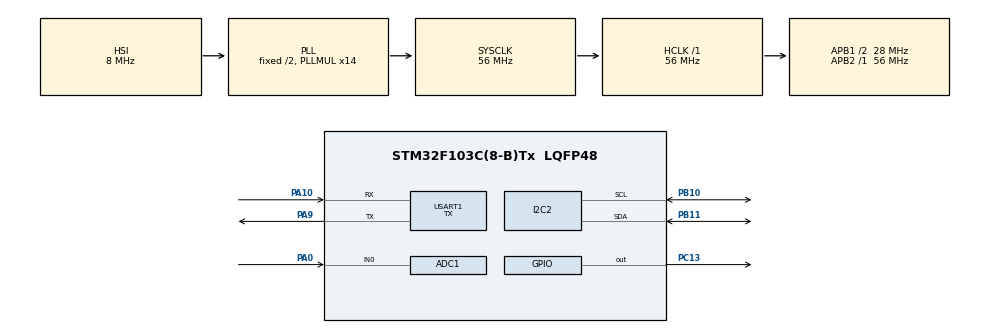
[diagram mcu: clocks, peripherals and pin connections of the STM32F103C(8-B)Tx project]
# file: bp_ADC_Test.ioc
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ADC1.Channel-0\#ChannelRegularConversion=ADC_CHANNEL_0
ADC1.NbrOfConversionFlag=1
ADC1.Rank-0\#ChannelRegularConversion=1
ADC1.SamplingTime-0\#ChannelRegularConversion=ADC_SAMPLETIME_1CYCLE_5
ADC1.master=1
I2C2.I2C_Mode=I2C_Fast
Mcu.Family=STM32F1
Mcu.Name=STM32F103C(8-B)Tx
Mcu.Package=LQFP48
NVIC.PriorityGroup=NVIC_PRIORITYGROUP_4
PA0-WKUP.Signal=ADCx_IN0
PA10.Mode=Asynchronous
PA10.Signal=USART1_RX
PA13.Mode=Serial_Wire
PA13.Signal=SYS_JTMS-SWDIO
PA14.Mode=Serial_Wire
PA14.Signal=SYS_JTCK-SWCLK
PA9.Mode=Asynchronous
PA9.Signal=USART1_TX
PB10.Mode=I2C
PB10.Signal=I2C2_SCL
PB11.Mode=I2C
PB11.Signal=I2C2_SDA
PC13-TAMPER-RTC.Signal=GPIO_Output
ProjectManager.HeapSize=0x200
ProjectManager.StackSize=0x400
ProjectManager.TargetToolchain=TrueSTUDIO
RCC.ADCPresc=RCC_ADCPCLK2_DIV4
RCC.AHBFreq_Value=56000000
RCC.APB1CLKDivider=RCC_HCLK_DIV2
RCC.APB1Freq_Value=28000000
RCC.APB1TimFreq_Value=56000000
RCC.APB2Freq_Value=56000000
RCC.APB2TimFreq_Value=56000000
RCC.HCLKFreq_Value=56000000
RCC.PLLMUL=RCC_PLL_MUL14
RCC.SYSCLKFreq_VALUE=56000000
RCC.SYSCLKSource=RCC_SYSCLKSOURCE_PLLCLK
RCC.USBFreq_Value=56000000
SH.ADCx_IN0.0=ADC1_IN0,IN0
USART1.Mode=MODE_TX
USART1.VirtualMode=VM_ASYNC
board=custom

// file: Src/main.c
/* USER CODE BEGIN Header */
/**
  ******************************************************************************
  * @file           : main.c
  * @brief          : Main program body
  ******************************************************************************
  ** This notice applies to any and all portions of this file
  * that are not between comment pairs USER CODE BEGIN and
  * USER CODE END. Other portions of this file, whether
  * inserted by the user or by software development tools
  * are owned by their respective copyright owners.
  *
  * COPYRIGHT(c) 2019 STMicroelectronics
  *
  * Redistribution and use in source and binary forms, with or without modification,
  * are permitted provided that the following conditions are met:
  *   1. Redistributions of source code must retain the above copyright notice,
  *      this list of conditions and the following disclaimer.
  *   2. Redistributions in binary form must reproduce the above copyright notice,
  *      this list of conditions and the following disclaimer in the documentation
  *      and/or other materials provided with the distribution.
  *   3. Neither the name of STMicroelectronics nor the names of its contributors
  *      may be used to endorse or promote products derived from this software
  *      without specific prior written permission.
  *
  * THIS SOFTWARE IS PROVIDED BY THE COPYRIGHT HOLDERS AND CONTRIBUTORS "AS IS"
  * AND ANY EXPRESS OR IMPLIED WARRANTIES, INCLUDING, BUT NOT LIMITED TO, THE
  * IMPLIED WARRANTIES OF MERCHANTABILITY AND FITNESS FOR A PARTICULAR PURPOSE ARE
  * DISCLAIMED. IN NO EVENT SHALL THE COPYRIGHT HOLDER OR CONTRIBUTORS BE LIABLE
  * FOR ANY DIRECT, INDIRECT, INCIDENTAL, SPECIAL, EXEMPLARY, OR CONSEQUENTIAL
  * DAMAGES (INCLUDING, BUT NOT LIMITED TO, PROCUREMENT OF SUBSTITUTE GOODS OR
  * SERVICES; LOSS OF USE, DATA, OR PROFITS; OR BUSINESS INTERRUPTION) HOWEVER
  * CAUSED AND ON ANY THEORY OF LIABILITY, WHETHER IN CONTRACT, STRICT LIABILITY,
  * OR TORT (INCLUDING NEGLIGENCE OR OTHERWISE) ARISING IN ANY WAY OUT OF THE USE
  * OF THIS SOFTWARE, EVEN IF ADVISED OF THE POSSIBILITY OF SUCH DAMAGE.
  *
  ******************************************************************************
  */
/* USER CODE END Header */

#include "main.h"

/* USER CODE BEGIN Includes */
#include "print_UART.h"

/* USER CODE END Includes */

ADC_HandleTypeDef hadc1;

I2C_HandleTypeDef hi2c2;

UART_HandleTypeDef huart1;

void SystemClock_Config(void);
static void MX_GPIO_Init(void);
static void MX_USART1_UART_Init(void);
static void MX_ADC1_Init(void);
static void MX_I2C2_Init(void);

int main(void)
{

  /* MCU Configuration--------------------------------------------------------*/

  /* Reset of all peripherals, Initializes the Flash interface and the Systick. */
  HAL_Init();

  /* Configure the system clock */
  SystemClock_Config();

  /* Initialize all configured peripherals */
  MX_GPIO_Init();
  MX_USART1_UART_Init();
  MX_ADC1_Init();
  MX_I2C2_Init();
  /* USER CODE BEGIN 2 */
  HAL_ADCEx_Calibration_Start(&hadc1);

  static uint16_t data_adc;
  static float data_adc_float;
  static float media=0;

  /* USER CODE END 2 */

  /* Infinite loop */
  /* USER CODE BEGIN WHILE */
  while (1)
  {

	  for (uint8_t i=0; i<50; i++){
		  HAL_ADC_Start(&hadc1);
		  HAL_ADC_PollForConversion(&hadc1, 1000);
		  data_adc = HAL_ADC_GetValue(&hadc1);
		  HAL_ADC_Stop(&hadc1);
		  data_adc_float = data_adc;
		  media = (media*i + data_adc_float*3.3/4095) / (i+1);

		  HAL_Delay(50);
	  }

	  tx_UART_float(&huart1, media,2, 10);
    /* USER CODE END WHILE */

  }
}

void SystemClock_Config(void)
{
  RCC_OscInitTypeDef RCC_OscInitStruct = {0};
  RCC_ClkInitTypeDef RCC_ClkInitStruct = {0};
  RCC_PeriphCLKInitTypeDef PeriphClkInit = {0};

  /**Initializes the CPU, AHB and APB busses clocks
  */
  RCC_OscInitStruct.OscillatorType = RCC_OSCILLATORTYPE_HSI;
  RCC_OscInitStruct.HSIState = RCC_HSI_ON;
  RCC_OscInitStruct.HSICalibrationValue = RCC_HSICALIBRATION_DEFAULT;
  RCC_OscInitStruct.PLL.PLLState = RCC_PLL_ON;
  RCC_OscInitStruct.PLL.PLLSource = RCC_PLLSOURCE_HSI_DIV2;
  RCC_OscInitStruct.PLL.PLLMUL = RCC_PLL_MUL14;
  if (HAL_RCC_OscConfig(&RCC_OscInitStruct) != HAL_OK)
  {
    Error_Handler();
  }
  /**Initializes the CPU, AHB and APB busses clocks
  */
  RCC_ClkInitStruct.ClockType = RCC_CLOCKTYPE_HCLK|RCC_CLOCKTYPE_SYSCLK
                              |RCC_CLOCKTYPE_PCLK1|RCC_CLOCKTYPE_PCLK2;
  RCC_ClkInitStruct.SYSCLKSource = RCC_SYSCLKSOURCE_PLLCLK;
  RCC_ClkInitStruct.AHBCLKDivider = RCC_SYSCLK_DIV1;
  RCC_ClkInitStruct.APB1CLKDivider = RCC_HCLK_DIV2;
  RCC_ClkInitStruct.APB2CLKDivider = RCC_HCLK_DIV1;

  if (HAL_RCC_ClockConfig(&RCC_ClkInitStruct, FLASH_LATENCY_2) != HAL_OK)
  {
    Error_Handler();
  }
  PeriphClkInit.PeriphClockSelection = RCC_PERIPHCLK_ADC;
  PeriphClkInit.AdcClockSelection = RCC_ADCPCLK2_DIV4;
  if (HAL_RCCEx_PeriphCLKConfig(&PeriphClkInit) != HAL_OK)
  {
    Error_Handler();
  }
}

static void MX_ADC1_Init(void)
{

  ADC_ChannelConfTypeDef sConfig = {0};

  /**Common config
  */
  hadc1.Instance = ADC1;
  hadc1.Init.ScanConvMode = ADC_SCAN_DISABLE;
  hadc1.Init.ContinuousConvMode = DISABLE;
  hadc1.Init.DiscontinuousConvMode = DISABLE;
  hadc1.Init.ExternalTrigConv = ADC_SOFTWARE_START;
  hadc1.Init.DataAlign = ADC_DATAALIGN_RIGHT;
  hadc1.Init.NbrOfConversion = 1;
  if (HAL_ADC_Init(&hadc1) != HAL_OK)
  {
    Error_Handler();
  }
  /**Configure Regular Channel
  */
  sConfig.Channel = ADC_CHANNEL_0;
  sConfig.Rank = ADC_REGULAR_RANK_1;
  sConfig.SamplingTime = ADC_SAMPLETIME_1CYCLE_5;
  if (HAL_ADC_ConfigChannel(&hadc1, &sConfig) != HAL_OK)
  {
    Error_Handler();
  }

}

static void MX_I2C2_Init(void)
{

  hi2c2.Instance = I2C2;
  hi2c2.Init.ClockSpeed = 400000;
  hi2c2.Init.DutyCycle = I2C_DUTYCYCLE_2;
  hi2c2.Init.OwnAddress1 = 0;
  hi2c2.Init.AddressingMode = I2C_ADDRESSINGMODE_7BIT;
  hi2c2.Init.DualAddressMode = I2C_DUALADDRESS_DISABLE;
  hi2c2.Init.OwnAddress2 = 0;
  hi2c2.Init.GeneralCallMode = I2C_GENERALCALL_DISABLE;
  hi2c2.Init.NoStretchMode = I2C_NOSTRETCH_DISABLE;
  if (HAL_I2C_Init(&hi2c2) != HAL_OK)
  {
    Error_Handler();
  }

}

static void MX_USART1_UART_Init(void)
{

  huart1.Instance = USART1;
  huart1.Init.BaudRate = 115200;
  huart1.Init.WordLength = UART_WORDLENGTH_8B;
  huart1.Init.StopBits = UART_STOPBITS_1;
  huart1.Init.Parity = UART_PARITY_NONE;
  huart1.Init.Mode = UART_MODE_TX;
  huart1.Init.HwFlowCtl = UART_HWCONTROL_NONE;
  huart1.Init.OverSampling = UART_OVERSAMPLING_16;
  if (HAL_UART_Init(&huart1) != HAL_OK)
  {
    Error_Handler();
  }

}

static void MX_GPIO_Init(void)
{
  GPIO_InitTypeDef GPIO_InitStruct = {0};

  /* GPIO Ports Clock Enable */
  __HAL_RCC_GPIOC_CLK_ENABLE();
  __HAL_RCC_GPIOA_CLK_ENABLE();
  __HAL_RCC_GPIOB_CLK_ENABLE();

  /*Configure GPIO pin Output Level */
  HAL_GPIO_WritePin(GPIOC, GPIO_PIN_13, GPIO_PIN_RESET);

  /*Configure GPIO pin : PC13 */
  GPIO_InitStruct.Pin = GPIO_PIN_13;
  GPIO_InitStruct.Mode = GPIO_MODE_OUTPUT_PP;
  GPIO_InitStruct.Pull = GPIO_NOPULL;
  GPIO_InitStruct.Speed = GPIO_SPEED_FREQ_LOW;
  HAL_GPIO_Init(GPIOC, &GPIO_InitStruct);

}

void Error_Handler(void)
{
}

/************************ (C) COPYRIGHT STMicroelectronics *****END OF FILE****/
